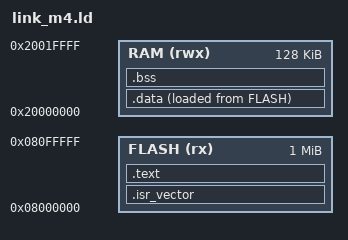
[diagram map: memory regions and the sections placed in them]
/* Minimal Cortex-M4 image for QEMU's netduinoplus2 (STM32F405 map, the nearest
 * model to the FXPak's F401). See docs/dev-mode.md tier 3. */
MEMORY {
  FLASH (rx) : ORIGIN = 0x08000000, LENGTH = 1024K
  RAM  (rwx) : ORIGIN = 0x20000000, LENGTH = 128K
}
_estack = ORIGIN(RAM) + LENGTH(RAM);

SECTIONS {
  .isr_vector : { KEEP(*(.isr_vector)) } > FLASH
  .text : { *(.text*) *(.rodata*) } > FLASH
  . = ALIGN(4);
  _sidata = LOADADDR(.data);
  .data : { _sdata = .; *(.data*) . = ALIGN(4); _edata = .; } > RAM AT> FLASH
  .bss  : { _sbss = .; *(.bss*) *(COMMON) . = ALIGN(4); _ebss = .; } > RAM
}
